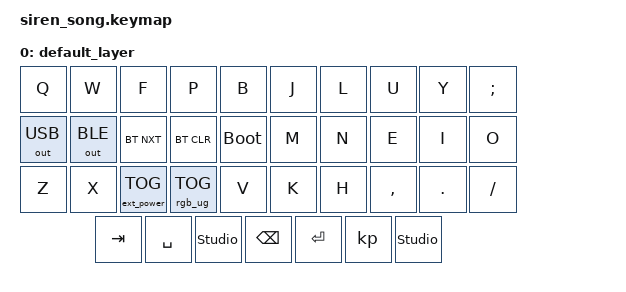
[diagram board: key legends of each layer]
#include <behaviors.dtsi>
#include <dt-bindings/zmk/keys.h>
#include <dt-bindings/zmk/outputs.h>
#include <dt-bindings/zmk/bt.h>
#include <dt-bindings/zmk/rgb.h>
#include <dt-bindings/zmk/ext_power.h>

/ {
    keymap {
        compatible = "zmk,keymap";

        default_layer { // Layer 0
            bindings = <
                &kp Q    &kp W    &kp F    &kp P    &kp B                              &kp J    &kp L    &kp U    &kp Y    &kp SEMICOLON
                &out OUT_USB    &out OUT_BLE    &bt BT_NXT    &bt BT_CLR    &bootloader                             &kp M    &kp N    &kp E    &kp I    &kp O
                &kp Z    &kp X    &ext_power EP_TOG    &rgb_ug RGB_TOG    &kp V                              &kp K    &kp H    &kp COMMA    &kp PERIOD    &kp SLASH
                                           &kp TAB    &kp SPACE    &studio_unlock            &kp BACKSPACE    &kp RETURN    &kp &studio_unlock
            >;
        };

        extra1 {
            status = "reserved";
        };

        extra2 {
            status = "reserved";
        };

        extra3 {
            status = "reserved";
        };

        extra4 {
            status = "reserved";
        };

        extra5 {
            status = "reserved";
        };

        extra6 {
            status = "reserved";
        };

        extra7 {
            status = "reserved";
        };

        extra8 {
            status = "reserved";
        };

        extra9 {
            status = "reserved";
        };

        extra10 {
            status = "reserved";
        };

        extra11 {
            status = "reserved";
        };

        extra12 {
            status = "reserved";
        };

        extra13 {
            status = "reserved";
        };

        extra14 {
            status = "reserved";
        };

        extra15 {
            status = "reserved";
        };

        extra16 {
            status = "reserved";
        };

        extra17 {
            status = "reserved";
        };

        extra18 {
            status = "reserved";
        };

        extra19 {
            status = "reserved";
        };

        extra20 {
            status = "reserved";
        };

        extra21 {
            status = "reserved";
        };

        extra22 {
            status = "reserved";
        };

        extra23 {
            status = "reserved";
        };

        extra24 {
            status = "reserved";
        };

        extra25 {
            status = "reserved";
        };

        extra26 {
            status = "reserved";
        };

        extra27 {
            status = "reserved";
        };

        extra28 {
            status = "reserved";
        };

        extra29 {
            status = "reserved";
        };

        extra30 {
            status = "reserved";
        };

        extra31 {
            status = "reserved";
        };
    };
};
&led_strip {
    chain-length = <18>;
};
